# PDMA10_REGS register map
Vendor: Texas Instruments
Peripheral module from a debugger description file (folder J7VCL).
Registers are 32-bit, access not given, reset 0x0 unless marked. A register's access mark holds for its fields unless they carry their own. Offsets are as the file gives them; lines under a group give offsets from that group; [hi:lo] are bit positions; {n}, {i} and the like mark numbered series; 'fields as' and 'values as' point back to an identical list; <NAME> marks a mode.

## PDMA10_REGS
0x00 PDMA10_ECC_REV ro reset 0x66A0EA00 — IP revision register.
  [31:0] REV — TI internal data. Identifies revision of peripheral.
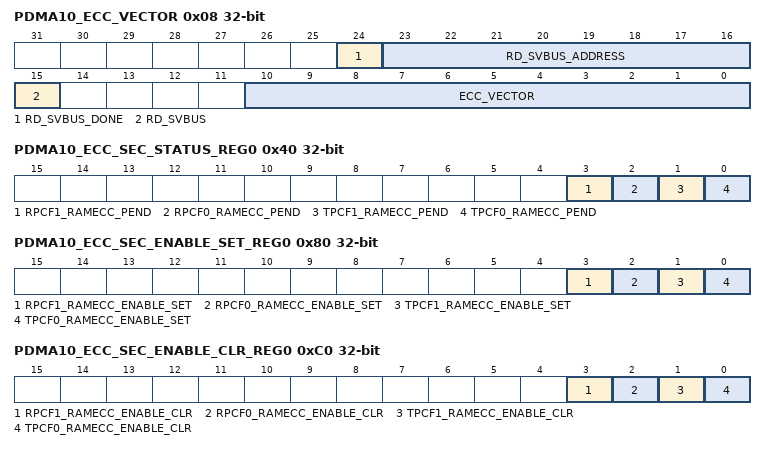
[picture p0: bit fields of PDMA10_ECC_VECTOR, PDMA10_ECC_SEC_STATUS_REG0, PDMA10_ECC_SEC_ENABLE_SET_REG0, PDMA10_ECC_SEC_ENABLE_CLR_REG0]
0x08 PDMA10_ECC_VECTOR — ECC vector register.
  [24] RD_SVBUS_DONE — Status to indicate if read on serial VBUS is complete, write of any value will clear this bit. (access RW1C)
  [23:16] RD_SVBUS_ADDRESS rw — Read address
  [15] RD_SVBUS — Write 1 to trigger a read on the serial VBUS (access RW1S)
  [10:0] ECC_VECTOR rw — Value written to select the corresponding ECC RAM for control or status
0x0C PDMA10_ECC_STAT ro reset 0x4 — Misc status register.
  [10:0] NUM_RAMS — Indicates the number of RAMs serviced by the ECC aggregator
0x3C PDMA10_ECC_SEC_EOI_REG — SEC EOI register. The EOI register is used to re-trigger the pulse interrupt signal to ensure that any nested interrupt events are serviced. The software interrupt handler must write to the EOI register at the end of the current interrupt processing routine, so that new events can re-trigger the pulse interrupt signal again. For level interrupt signals the EOI register is not functional and must not be used.
  [0] EOI_WR — EOI value (access RW1S)
0x40 PDMA10_ECC_SEC_STATUS_REG0 — SEC interrupt status register 0.
  [3] RPCF1_RAMECC_PEND — Interrupt pending status for rpcf1_ramecc_pend (access RW1S)
  [2] RPCF0_RAMECC_PEND — Interrupt pending status for rpcf0_ramecc_pend (access RW1S)
  [1] TPCF1_RAMECC_PEND — Interrupt pending status for tpcf1_ramecc_pend (access RW1S)
  [0] TPCF0_RAMECC_PEND — Interrupt pending status for tpcf0_ramecc_pend (access RW1S)
0x80 PDMA10_ECC_SEC_ENABLE_SET_REG0 — SEC interrupt enable set register 0.
  [3] RPCF1_RAMECC_ENABLE_SET — Interrupt enable set register for rpcf1_ramecc_pend (access RW1S)
  [2] RPCF0_RAMECC_ENABLE_SET — Interrupt enable set register for rpcf0_ramecc_pend (access RW1S)
  [1] TPCF1_RAMECC_ENABLE_SET — Interrupt enable set register for tpcf1_ramecc_pend (access RW1S)
  [0] TPCF0_RAMECC_ENABLE_SET — Interrupt enable set register for tpcf0_ramecc_pend (access RW1S)
0xC0 PDMA10_ECC_SEC_ENABLE_CLR_REG0 — SEC interrupt enable clear register 0.
  [3] RPCF1_RAMECC_ENABLE_CLR — Interrupt enable clear register for rpcf1_ramecc_pend (access RW1C)
  [2] RPCF0_RAMECC_ENABLE_CLR — Interrupt enable clear register for rpcf0_ramecc_pend (access RW1C)
  [1] TPCF1_RAMECC_ENABLE_CLR — Interrupt enable clear register for tpcf1_ramecc_pend (access RW1C)
  [0] TPCF0_RAMECC_ENABLE_CLR — Interrupt enable clear register for tpcf0_ramecc_pend (access RW1C)
0x13C PDMA10_ECC_DED_EOI_REG — DED EOI register. The EOI register is used to re-trigger the pulse interrupt signal to ensure that any nested interrupt events are serviced. The software interrupt handler must write to the EOI register at the end of the current interrupt processing routine, so that new events can re-trigger the pulse interrupt signal again. For level interrupt signals the EOI register is not functional and must not be used.
  [0] EOI_WR — EOI value (access RW1S)
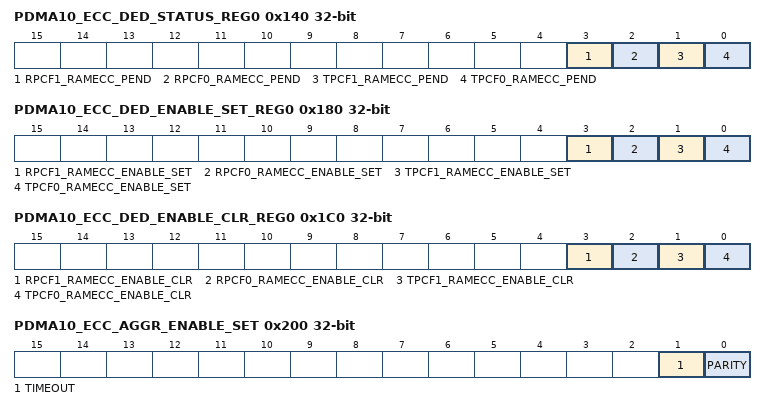
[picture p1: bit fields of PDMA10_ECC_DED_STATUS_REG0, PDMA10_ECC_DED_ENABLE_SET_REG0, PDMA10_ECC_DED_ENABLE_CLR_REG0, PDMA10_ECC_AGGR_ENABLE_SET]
0x140 PDMA10_ECC_DED_STATUS_REG0 — DED interrupt status register 0.
  fields as PDMA10_ECC_SEC_STATUS_REG0
0x180 PDMA10_ECC_DED_ENABLE_SET_REG0 — DED interrupt enable set register 0.
  fields as PDMA10_ECC_SEC_ENABLE_SET_REG0
0x1C0 PDMA10_ECC_DED_ENABLE_CLR_REG0 — DED interrupt enable clear register 0.
  fields as PDMA10_ECC_SEC_ENABLE_CLR_REG0
0x200 PDMA10_ECC_AGGR_ENABLE_SET — AGGR interrupt enable set register.
  [1] TIMEOUT — Interrupt enable set for svbus timeout errors (access RW1S)
  [0] PARITY — Interrupt enable set for parity errors (access RW1S)
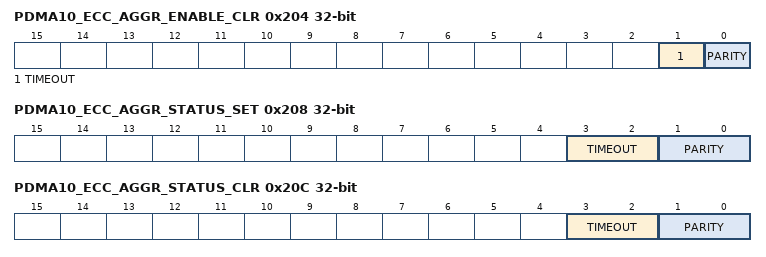
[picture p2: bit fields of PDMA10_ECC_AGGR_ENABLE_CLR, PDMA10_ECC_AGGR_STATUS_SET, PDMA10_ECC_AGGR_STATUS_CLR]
0x204 PDMA10_ECC_AGGR_ENABLE_CLR — AGGR interrupt enable clear register.
  [1] TIMEOUT — Interrupt enable clear for svbus timeout errors (access RW1C)
  [0] PARITY — Interrupt enable clear for parity errors (access RW1C)
0x208 PDMA10_ECC_AGGR_STATUS_SET — AGGR interrupt status set register.
  [3:2] TIMEOUT — Interrupt status set for svbus timeout errors (access RWincr)
  [1:0] PARITY — Interrupt status set for parity errors (access RWincr)
0x20C PDMA10_ECC_AGGR_STATUS_CLR — AGGR interrupt status clear register.
  [3:2] TIMEOUT — Interrupt status clear for svbus timeout errors (access RWdecr)
  [1:0] PARITY — Interrupt status clear for parity errors (access RWdecr)
